# STM32G041xx register map
File version: 1.0
Registers are 32-bit, read-write, reset 0x0 unless marked. A register's access mark holds for its fields unless they carry their own. Offsets are from the block's base; [hi:lo] are bit positions; {n}, {i} and the like mark numbered series.

## I2C2 — Inter-integrated Circuit Interface
Base 0x40005800
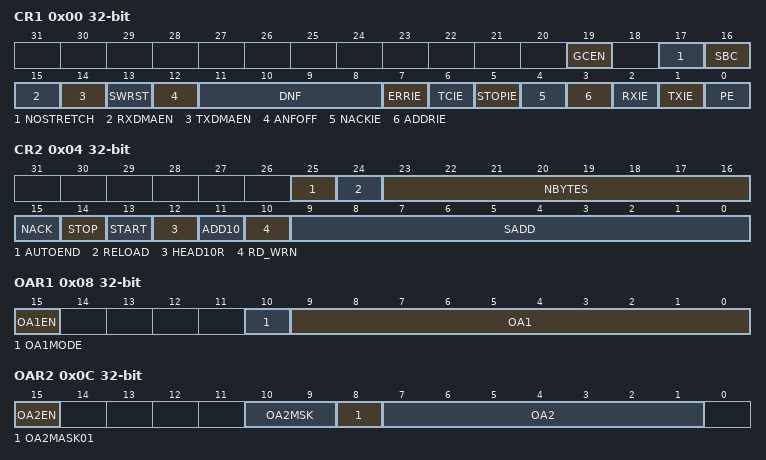
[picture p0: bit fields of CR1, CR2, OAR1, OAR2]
0x00 CR1 — I2C Control register 1
  [19] GCEN — General call enable
  [17] NOSTRETCH — Clock stretching disable
  [16] SBC — Slave byte control
  [15] RXDMAEN — DMA reception requests enable
  [14] TXDMAEN — DMA transmission requests enable
  [13] SWRST — Software reset
  [12] ANFOFF — Analog noise filter OFF
  [11:8] DNF — Digital noise filter
  [7] ERRIE — Errors interrupt enable
  [6] TCIE — Transfer complete interrupt enable
  [5] STOPIE — STOP detection interrupt enable
  [4] NACKIE — NACK received interrupt enable
  [3] ADDRIE — Address match interrupt enable
  [2] RXIE — RX interrupt enable
  [1] TXIE — TX interrupt enable
  [0] PE — Peripheral enable
0x04 CR2 — I2C Control register 2
  [25] AUTOEND — Automatic end mode (master mode)
  [24] RELOAD — NBYTES reload mode
  [23:16] NBYTES — Number of bytes
  [15] NACK — NACK generation (slave mode)
    0=ACK (ACK is sent after current received byte.); 1=NACK (NACK is sent after current received byte.)
  [14] STOP — STOP generation (master mode)
  [13] START — START generation
  [12] HEAD10R — 10-bit address header only read direction (master mode)
  [11] ADD10 — 10-bit addressing mode (master mode)
    0=MODE_7BIT (Master operates in 7-bit addressing mode.); 1=MODE_10BIT (Master operates in 10-bit addressing mode.)
  [10] RD_WRN — Transfer direction (master mode)
    0=WRITE (Master request a write transfer.); 1=READ (Master request a read transfer.)
  [9:0] SADD — Slave address (master mode)
0x08 OAR1 — I2C Own address 1 register
  [15] OA1EN — Own address 1 enable
  [10] OA1MODE — Own address 1 10-bit mode
  [9:0] OA1 — Interface own address 1
0x0C OAR2 — I2C Own address 2 register
  [15] OA2EN — Own address 2 enable
  [10:9] OA2MSK — Own address 2 masks
  [8] OA2MASK01 — OA2[1] is masked, Only OA2[7:2] are compared
  [7:1] OA2 — Interface own address 2
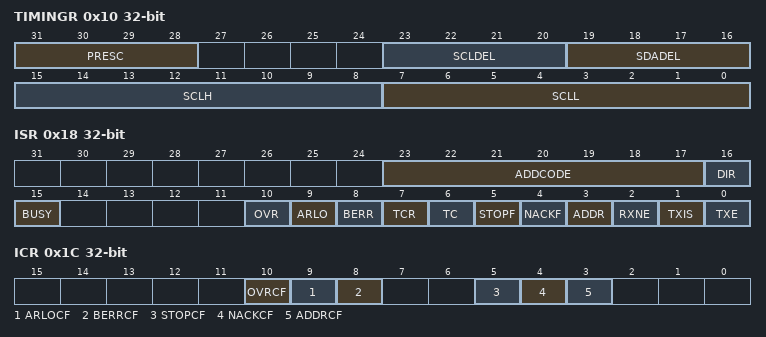
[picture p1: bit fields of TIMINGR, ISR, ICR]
0x10 TIMINGR — I2C Timing register
  [31:28] PRESC — Timings prescaler
  [23:20] SCLDEL — Data setup time
  [19:16] SDADEL — Data hold time
  [15:8] SCLH — SCL high period (master mode)
  [7:0] SCLL — SCL low period (master mode)
0x18 ISR — I2C Interrupt and status register
  [23:17] ADDCODE — Address match code (slave mode)
  [16] DIR — Transfer direction (slave mode)
    0=WRITE; 1=READ
  [15] BUSY — Bus busy
  [10] OVR — Overrun/Underrun
  [9] ARLO — Arbitration lost
  [8] BERR — Bus error
  [7] TCR — Transfer complete reload
  [6] TC — Transfer complete (master mode)
  [5] STOPF — STOP detection flag
  [4] NACKF — NACK received flag
  [3] ADDR — Address matched (slave mode)
  [2] RXNE — Receive data register not empty
  [1] TXIS — Transmit interrupt status
  [0] TXE — Transmit data register empty
0x1C ICR — I2C Interrupt clear register
  [10] OVRCF — Overrun/Underrun clear flag
  [9] ARLOCF — Arbitration lost clear flag
  [8] BERRCF — Bus error clear flag
  [5] STOPCF — STOP detection clear flag
  [4] NACKCF — NACK clear flag
  [3] ADDRCF — Address matched clear flag
0x24 RXDR — I2C Receive data register
  [7:0] RXDATA — 8-bit receive data
0x28 TXDR — I2C Transmit data register
  [7:0] TXDATA — 8-bit transmit data

## PWR — Power Control
Base 0x40007000
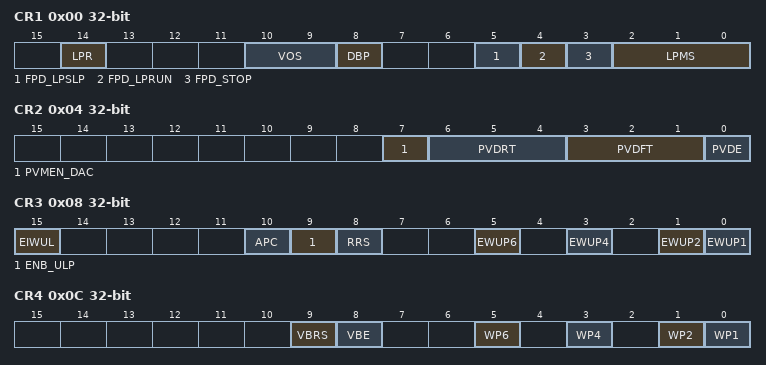
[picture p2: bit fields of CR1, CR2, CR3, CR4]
0x00 CR1 — PWR Power Control Register 1
  [14] LPR — Regulator Low-Power Run mode
  [10:9] VOS — Voltage scaling
    1=SCALE1; 2=SCALE2
  [8] DBP — Disable Backup Domain write protection
  [5] FPD_LPSLP — Flash power down mode during sleep
  [4] FPD_LPRUN — Flash power down mode during run
  [3] FPD_STOP — Flash power down mode during stop
  [2:0] LPMS — Low Power Mode Selection
    0=STOP0; 1=STOP1; 3=STANDBY; 4=SHUTDOWN
0x04 CR2 — PWR Power Control Register 2
  [7] PVMEN_DAC — DAC supply voltage monitoring enable
  [6:4] PVDRT — PVD Rising Threshold Selection bit field
    {v}=PVDHLEVEL_{v} (v=0..7)
  [3:1] PVDFT — PVD Falling Threshold Selection bit field
    {v}=PVDLLEVEL_{v} (v=0..6)
  [0] PVDE — Programmable Voltage Detector Enable
0x08 CR3 — PWR Power Control Register 3
  [15] EIWUL — Enable Internal Wake-up line
  [10] APC — Apply pull-up and pull-down configuration
  [9] ENB_ULP — Enable sampling resistor bridge in the LPMU_RESET block
  [8] RRS — RAM retention in Standby mode
  [5] EWUP6 — Enable WKUP pin 6
  [3] EWUP4 — Enable WKUP pin 4
  [1] EWUP2 — Enable WKUP pin 2
  [0] EWUP1 — Enable WKUP pin 1
0x0C CR4 — PWR Power Control Register 4
  [9] VBRS — VBAT Battery charging Resistor Selection
    0=RESISTOR_5K; 1=RESISTOR_1_5K
  [8] VBE — VBAT Battery charging Enable
  [5] WP6 — Wake-Up Pin 6 polarity
  [3] WP4 — Wake-Up Pin 4 polarity
  [1] WP2 — Wake-Up Pin 2 polarity
  [0] WP1 — Wake-Up Pin 1 polarity
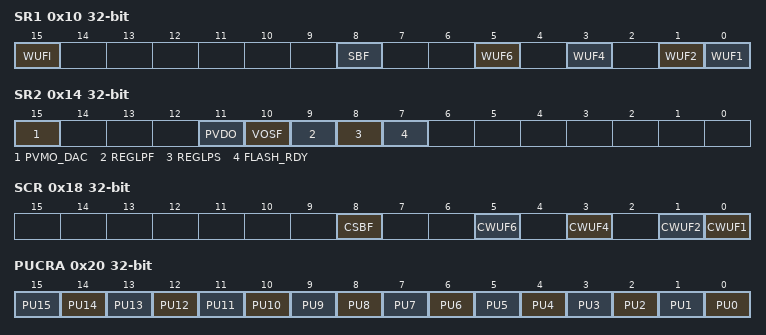
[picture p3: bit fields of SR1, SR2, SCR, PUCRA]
0x10 SR1 — PWR Power Status Register 1
  [15] WUFI — Wakeup Flag Internal
  [8] SBF — Standby Flag
  [5] WUF6 — Wakeup Flag 6
  [3] WUF4 — Wakeup Flag 4
  [1] WUF2 — Wakeup Flag 2
  [0] WUF1 — Wakeup Flag 1
0x14 SR2 — PWR Power Status Register 2
  [15] PVMO_DAC — VDDA monitoring output flag
  [11] PVDO — Power voltage detector output
  [10] VOSF — Voltage Scaling Flag
  [9] REGLPF — Regulator Low Power flag
  [8] REGLPS — Regulator Low Power started
  [7] FLASH_RDY — Flash Ready
0x18 SCR — PWR Power Status Clear Register
  [8] CSBF — Clear Standby Flag
  [5] CWUF6 — Clear Wake-up Flag 6
  [3] CWUF4 — Clear Wake-up Flag 4
  [1] CWUF2 — Clear Wake-up Flag 2
  [0] CWUF1 — Clear Wake-up Flag 1
0x20 PUCRA — PWR Pull-Up Control Register of port A
  [n] PU{n} (n=0..15) — Pin PA{n} Pull-Up set
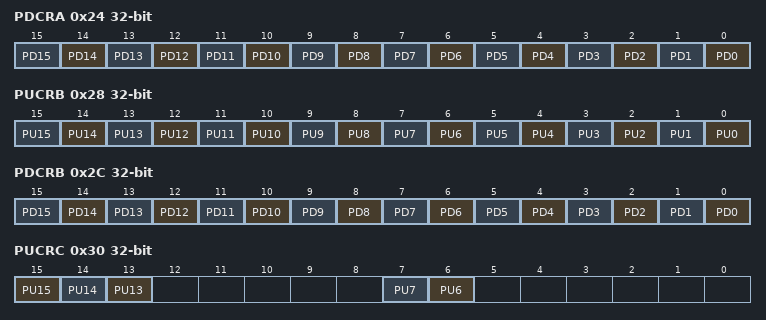
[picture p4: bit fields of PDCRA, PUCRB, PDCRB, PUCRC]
0x24 PDCRA — PWR Pull-Down Control Register of port A
  [n] PD{n} (n=0..15) — Pin PA{n} Pull-Down set
0x28 PUCRB — PWR Pull-Up Control Register of port B
  [n] PU{n} (n=0..15) — Pin PB{n} Pull-Up set
0x2C PDCRB — PWR Pull-Down Control Register of port B
  [n] PD{n} (n=0..15) — Pin PB{n} Pull-Down set
0x30 PUCRC — PWR Pull-Up Control Register of port C
  [15] PU15 — Pin PC15 Pull-Up set
  [14] PU14 — Pin PC14 Pull-Up set
  [13] PU13 — Pin PC13 Pull-Up set
  [7] PU7 — Pin PC7 Pull-Up set
  [6] PU6 — Pin PC6 Pull-Up set
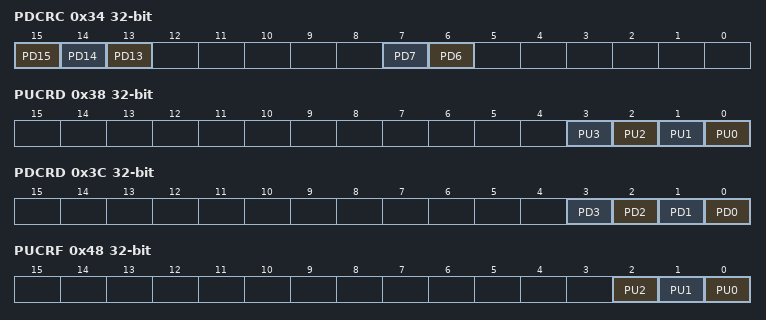
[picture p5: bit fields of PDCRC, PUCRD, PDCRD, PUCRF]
0x34 PDCRC — PWR Pull-Down Control Register of port C
  [15] PD15 — Pin PC15 Pull-Down set
  [14] PD14 — Pin PC14 Pull-Down set
  [13] PD13 — Pin PC13 Pull-Down set
  [7] PD7 — Pin PC7 Pull-Down set
  [6] PD6 — Pin PC6 Pull-Down set
0x38 PUCRD — PWR Pull-Up Control Register of port D
  [n] PU{n} (n=0..3) — Pin PD{n} Pull-Up set
0x3C PDCRD — PWR Pull-Down Control Register of port D
  [n] PD{n} (n=0..3) — Pin PD{n} Pull-Down set
0x48 PUCRF — PWR Pull-Up Control Register of port F
  [2] PU2 — Pin PF2 Pull-Up set
  [1] PU1 — Pin PF1 Pull-Up set
  [0] PU0 — Pin PF0 Pull-Up set
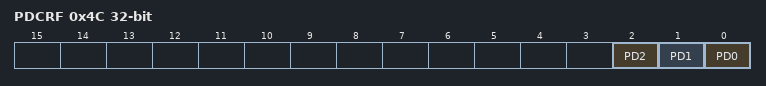
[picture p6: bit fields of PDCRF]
0x4C PDCRF — PWR Pull-Down Control Register of port F
  [2] PD2 — Pin PF2 Pull-Down set
  [1] PD1 — Pin PF1 Pull-Down set
  [0] PD0 — Pin PF0 Pull-Down set
